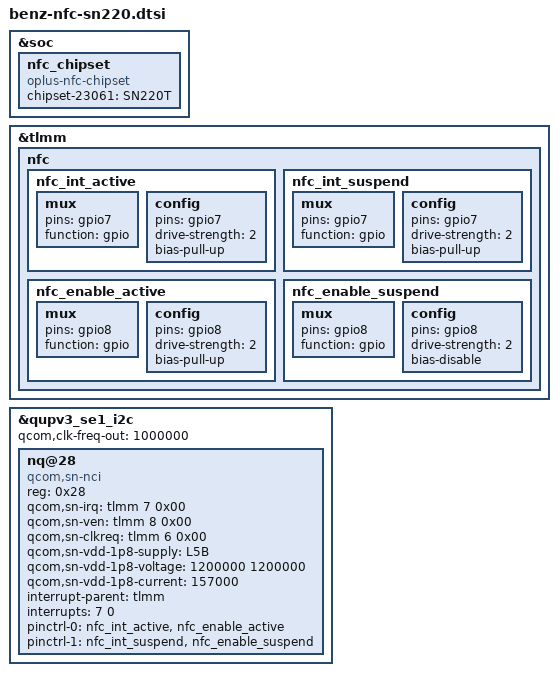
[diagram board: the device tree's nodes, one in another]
#include <dt-bindings/clock/qcom,rpmh.h>

&soc {
    //add for nfc_chipset
    nfc_chipset {
        compatible = "oplus-nfc-chipset";
        chipset-23061 = "SN220T";
    };
};


&tlmm {
	nfc {
		nfc_int_active: nfc_int_active {
			/* active state */
			mux {
				/* GPIO 7 NFC Read Interrupt */
				pins = "gpio7";
				function = "gpio";
			};

			config {
				pins = "gpio7";
				drive-strength = <2>; /* 2 MA */
				bias-pull-up;
			};
		};

		nfc_int_suspend: nfc_int_suspend {
			/* sleep state */
			mux {
				/* GPIO 7 NFC Read Interrupt */
				pins = "gpio7";
				function = "gpio";
			};

			config {
				pins = "gpio7";
				drive-strength = <2>; /* 2 MA */
				bias-pull-up;
			};
		};

		nfc_enable_active: nfc_enable_active {
			mux {
				pins = "gpio8";
				function = "gpio";
			};

			config {
				pins = "gpio8";
				drive-strength = <2>; /* 2 MA */
				bias-pull-up;
			};
		};

		nfc_enable_suspend: nfc_enable_suspend {
			mux {
				pins = "gpio8";
				function = "gpio";
			};

			config {
				pins = "gpio8";
				drive-strength = <2>; /* 2 MA */
				bias-disable;
			};
		};
	};
};


&qupv3_se1_i2c {
	status = "ok";
	qcom,clk-freq-out = <1000000>;
	#address-cells = <1>;
	#size-cells = <0>;
	nq@28 {
		compatible = "qcom,sn-nci";
		reg = <0x28>;
 		qcom,sn-irq = <&tlmm 7 0x00>;
 		qcom,sn-ven = <&tlmm 8 0x00>;
 		qcom,sn-clkreq = <&tlmm 6 0x00>;
 		qcom,sn-vdd-1p8-supply = <&L5B>;
 		qcom,sn-vdd-1p8-voltage = <1200000 1200000>;
 		qcom,sn-vdd-1p8-current = <157000>;
 		interrupt-parent = <&tlmm>;
 		interrupts = <7 0>;
 		interrupt-names = "nfc_irq";
 		pinctrl-names = "nfc_active", "nfc_suspend";
 		pinctrl-0 = <&nfc_int_active &nfc_enable_active>;
 		pinctrl-1 = <&nfc_int_suspend &nfc_enable_suspend>;
	};
};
